# GD32A503 register map
File version: 1.0
CPU: CM33 r0p4, little endian, MPU, FPU, 4 interrupt priority bits
Registers are 32-bit, read-write, reset 0x0 unless marked. A register's access mark holds for its fields unless they carry their own. Offsets are from the block's base; [hi:lo] are bit positions; {n}, {i} and the like mark numbered series.

## TIMER1 — General-purpose-timers
Base 0x40000000
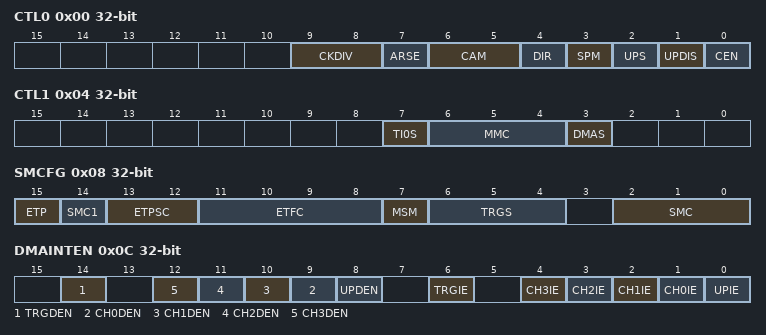
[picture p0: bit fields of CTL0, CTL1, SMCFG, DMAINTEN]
0x00 CTL0 — control register 0
  [9:8] CKDIV — Clock division
  [7] ARSE — Auto-reload shadow enable
  [6:5] CAM — Counter aligns mode selection
  [4] DIR — Direction
  [3] SPM — Single pulse mode
  [2] UPS — Update source
  [1] UPDIS — Update disable
  [0] CEN — Counter enable
0x04 CTL1 — control register 1
  [7] TI0S — Channel 0 trigger input selection
  [6:4] MMC — Master mode control
  [3] DMAS — DMA request source selection
0x08 SMCFG — slave mode control register
  [15] ETP — External trigger polarity
  [14] SMC1 — Part of SMC for enable External clock mode1
  [13:12] ETPSC — External trigger prescaler
  [11:8] ETFC — External trigger filter control
  [7] MSM — Master-slave mode
  [6:4] TRGS — Trigger selection
  [2:0] SMC — Slave mode control
0x0C DMAINTEN — DMA/Interrupt enable register
  [14] TRGDEN — Trigger DMA request enable
  [n+9] CH{n}DEN (n=0..3) — Channel {n} capture/compare DMA request enable
  [8] UPDEN — Update DMA request enable
  [6] TRGIE — Trigger interrupt enable
  [n+1] CH{n}IE (n=0..3) — Channel {n} capture/compare interrupt enable
  [0] UPIE — Update interrupt enable
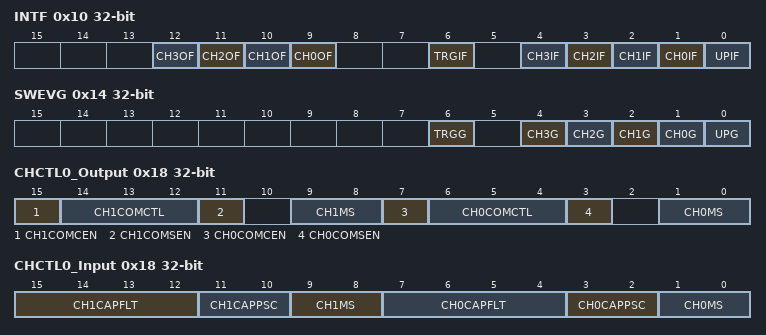
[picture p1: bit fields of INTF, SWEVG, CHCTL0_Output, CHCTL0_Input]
0x10 INTF — interrupt flag register
  [n+9] CH{n}OF (n=0..3) — Channel {n} over capture flag
  [6] TRGIF — Trigger interrupt flag
  [4] CH3IF — Channel 3 capture/compare interrupt enable
  [3] CH2IF — Channel 2 capture/compare interrupt enable
  [2] CH1IF — Channel 1 capture/compare interrupt flag
  [1] CH0IF — Channel 0 capture/compare interrupt flag
  [0] UPIF — Update interrupt flag
0x14 SWEVG wo — event generation register
  [6] TRGG — Trigger event generation
  [n+1] CH{n}G (n=0..3) — Channel {n} capture or compare event generation
  [0] UPG — Update generation
0x18 CHCTL0_Output — Channel control register 0 (output mode)
  [15] CH1COMCEN — Channel 1 output compare clear enable
  [14:12] CH1COMCTL — Channel 1 compare output control
  [11] CH1COMSEN — Channel 1 output compare shadow enable
  [9:8] CH1MS — Channel 1 mode selection
  [7] CH0COMCEN — Channel 0 output compare clear enable
  [6:4] CH0COMCTL — Channel 0 compare output control
  [3] CH0COMSEN — Channel 0 compare output shadow enable
  [1:0] CH0MS — Channel 0 I/O mode selection
0x18 CHCTL0_Input (alternate view of CHCTL0_Output) — Channel control register 0 (input mode)
  [15:12] CH1CAPFLT — Channel 1 input capture filter control
  [11:10] CH1CAPPSC — Channel 1 input capture prescaler
  [9:8] CH1MS — Channel 1 mode selection
  [7:4] CH0CAPFLT — Channel 0 input capture filter control
  [3:2] CH0CAPPSC — Channel 0 input capture prescaler
  [1:0] CH0MS — Channel 0 mode selection
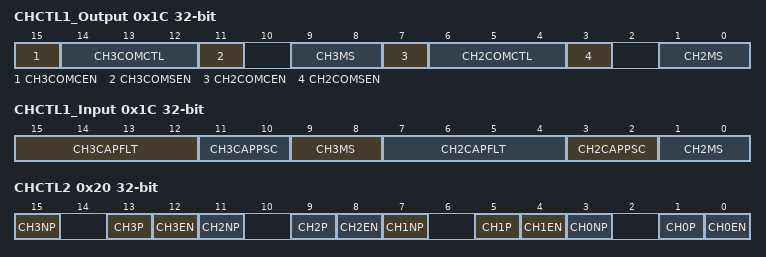
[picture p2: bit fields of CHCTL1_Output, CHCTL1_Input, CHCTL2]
0x1C CHCTL1_Output — Channel control register 1 (output mode)
  [15] CH3COMCEN — Channel 3 output compare clear enable
  [14:12] CH3COMCTL — Channel 3 compare output control
  [11] CH3COMSEN — Channel 3 output compare shadow enable
  [9:8] CH3MS — Channel 3 mode selection
  [7] CH2COMCEN — Channel 2 output compare clear enable
  [6:4] CH2COMCTL — Channel 2 compare output control
  [3] CH2COMSEN — Channel 2 compare output shadow enable
  [1:0] CH2MS — Channel 2 I/O mode selection
0x1C CHCTL1_Input (alternate view of CHCTL1_Output) — Channel control register 1 (input mode)
  [15:12] CH3CAPFLT — Channel 3 input capture filter control
  [11:10] CH3CAPPSC — Channel 3 input capture prescaler
  [9:8] CH3MS — Channel 3 mode selection
  [7:4] CH2CAPFLT — Channel 2 input capture filter control
  [3:2] CH2CAPPSC — Channel 2 input capture prescaler
  [1:0] CH2MS — Channel 2 mode selection
0x20 CHCTL2 — Channel control register 2
  [15] CH3NP — Channel 3 complementary capture/compare polarity
  [4n+1] CH{n}P (n=0..3) — Channel {n} capture/compare function polarity
  [4n] CH{n}EN (n=0..3) — Channel {n} capture/compare function enable
  [11] CH2NP — Channel 2 complementary capture/compare polarity
  [7] CH1NP — Channel 1 complementary capture/compare polarity
  [3] CH0NP — Channel 0 complementary output polarity
0x24 CNT — Counter register
  [15:0] CNT — counter value
0x28 PSC — Prescaler register
  [15:0] PSC — Prescaler value of the counter clock
0x2C CAR — Counter auto reload register
  [15:0] CARL — Counter auto reload value
0x34 CH0CV — Channel 0 capture/compare value register
  [15:0] CH0VAL — Capture or compare value of channel 0
0x38 CH1CV — Channel 1 capture/compare value register
  [15:0] CH1VAL — Capture or compare value of channel1
0x3C CH2CV — Channel 2 capture/compare value register
  [15:0] CH2VAL — Capture or compare value of channel 2
0x40 CH3CV — Channel 3 capture/compare value register
  [15:0] CH3VAL — Capture or compare value of channel 3
0x50 IRMP — Channel input remap register
  [1:0] CI0_RMP — Channel 0 input remap
0xFC CFG — Configuration
  [1] CHVSEL — Write CHxVAL register selection
